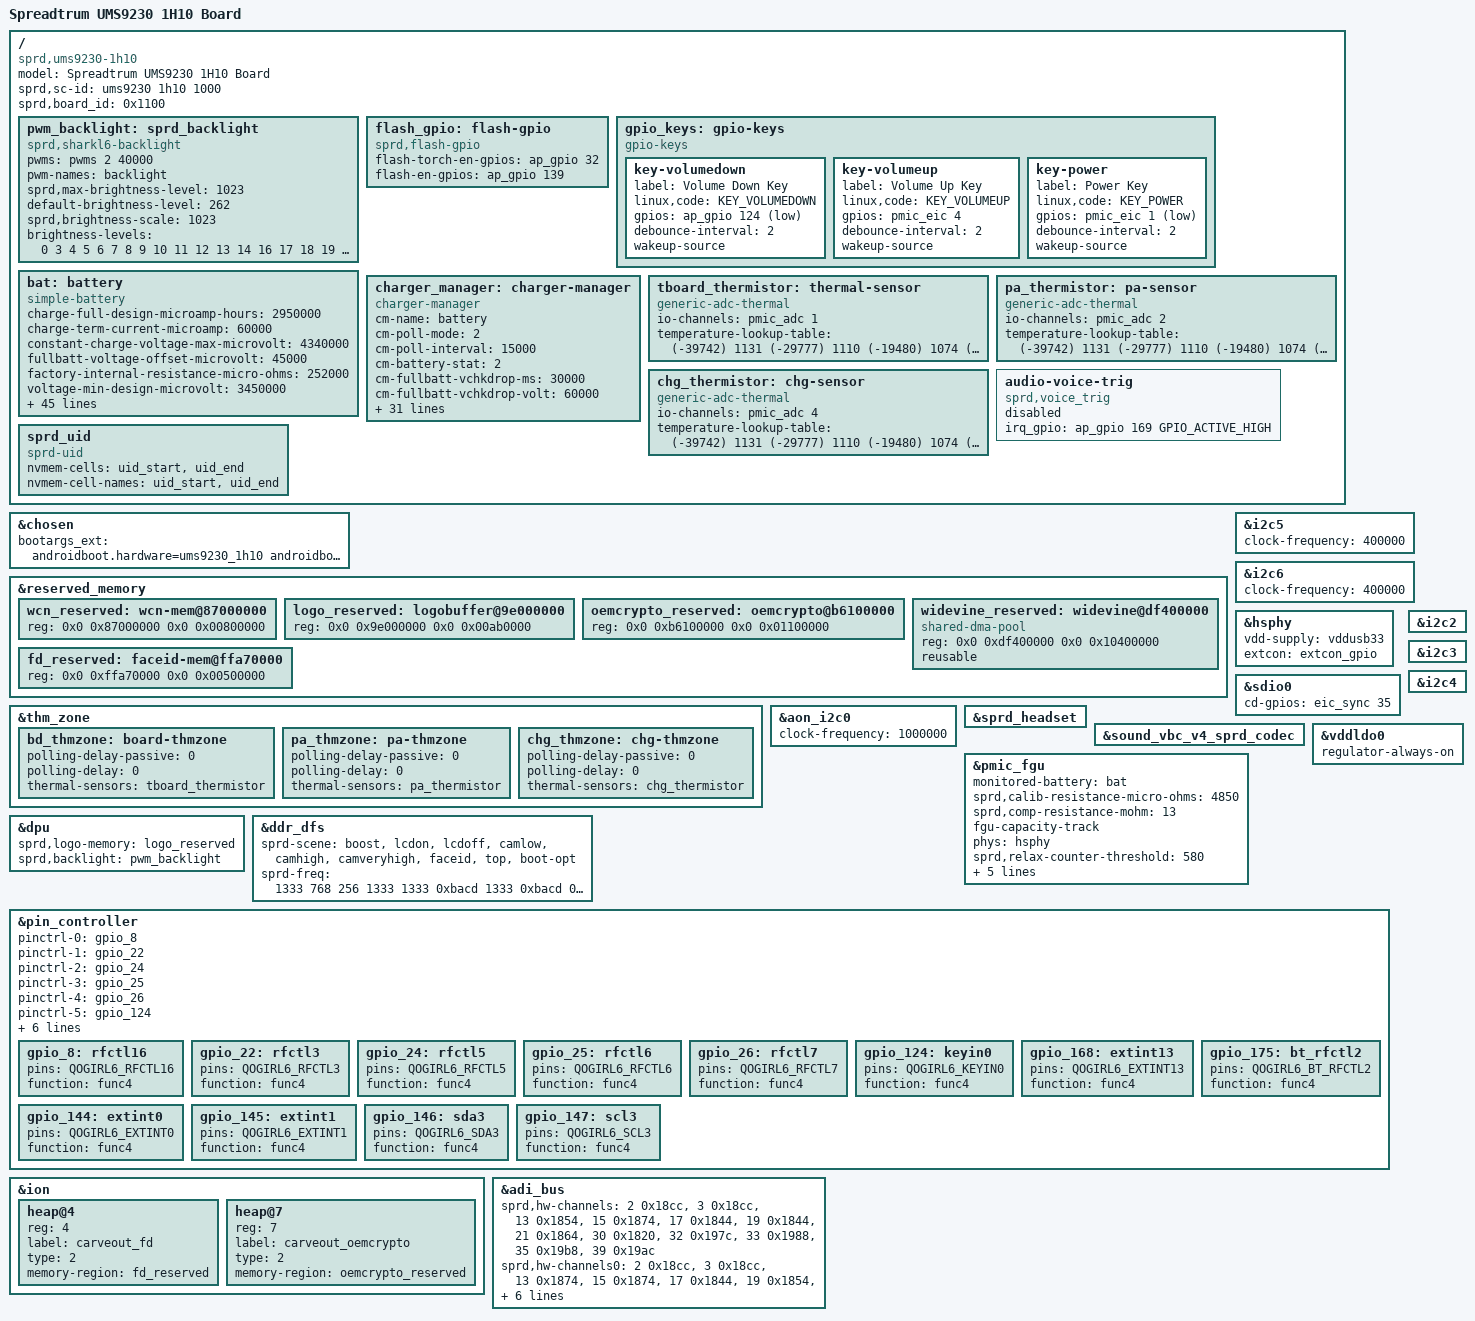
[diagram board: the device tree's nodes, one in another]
/dts-v1/;
/plugin/;
#include <dt-bindings/input/input.h>
#include <dt-bindings/gpio/gpio.h>
#include <dt-bindings/interrupt-controller/arm-gic.h>
#include <dt-bindings/clock/sprd,ums9230-clk.h>
#include <dt-bindings/mfd/sprd,sc2730-regs.h>
#include <dt-bindings/mfd/sprd,sc2730-mask.h>
#include <dt-bindings/usb/pd.h>
#include "ums9230-wcn.dtsi"
#include "lcd/lcd_dummy_mipi.dtsi"

/ {

	model = "Spreadtrum UMS9230 1H10 Board";

	compatible = "sprd,ums9230-1h10";

	sprd,sc-id = "ums9230 1h10 1000";

	sprd,board_id = <0x1100>; //XX00:base board,XX00~XXFF:customize board

	fragment {
		target-path = "/";
		__overlay__ {
			pwm_backlight: sprd_backlight {
				compatible = "sprd,sharkl6-backlight";
				pwms = <&pwms 2 40000>;
				pwm-names = "backlight";
				sprd,max-brightness-level = <1023>;
				default-brightness-level = <262>;
				sprd,brightness-scale = <1023>;
				brightness-levels = <
							  0   3   4   5   6   7
					  8   9  10  11  12  13  14  16  17  18
					 19  20  21  22  23  24  25  26  27  28
					 29  31  33  35  37  39  41  43  45  47
					 48  50  52  54  56  58  60  62  64  67
					 69  72  74  76  78  80  82  84  86  88
					 90  92  94  96  98 100 102 104 107 109
					112 114 116 118 120 122 124 126 128 130
					132 134 136 138 140 142 144 147 149 151
					154 156 158 160 162 164 166 168 170 172
					175 178 181 184 187 190 193 196 199 203
					205 208 211 214 217 220 223 226 229 234
					237 240 243 247 250 253 256 259 263 266
					269 270 274 277 280 283 287 290 294 297
					300 303 307 310 314 318 325 329 334 339
					340 343 347 350 354 358 365 369 374 380
					382 385 389 392 396 400 407 411 416 422
					426 430 434 438 442 446 452 457 460 464
					470 474 480 486 492 498 504 508 512 516
					522 527 532 536 540 545 550 555 561 568
					574 579 584 589 594 600 605 610 615 620
					625 630 635 641 647 652 657 662 667 673
					688 694 700 706 712 716 720 725 730 735
					740 746 752 758 764 770 776 782 790 798
					803 810 817 825 832 840 845 850 855 861
					866 872 878 884 890 896 903 911 918 924
				>;
			};

			flash_gpio: flash-gpio {
				compatible = "sprd,flash-gpio";
				flash-torch-en-gpios = <&ap_gpio 32 0>;
				flash-en-gpios = <&ap_gpio 139 0>;
			};

/*
			fingerprint@0 {
				compatible = "microarray,afs121";
				fpint-gpios = <&eic_async 29 0>;
			};
*/

			gpio_keys: gpio-keys {
				compatible = "gpio-keys";

				key-volumedown {
					label = "Volume Down Key";
					linux,code = <KEY_VOLUMEDOWN>;
					gpios = <&ap_gpio 124 GPIO_ACTIVE_LOW>;
					debounce-interval = <2>;
					wakeup-source;
				};

				key-volumeup {
					label = "Volume Up Key";
					linux,code = <KEY_VOLUMEUP>;
					gpios = <&pmic_eic 4 GPIO_ACTIVE_HIGH>;
					debounce-interval = <2>;
					wakeup-source;
				};

				key-power {
					label = "Power Key";
					linux,code = <KEY_POWER>;
					gpios = <&pmic_eic 1 GPIO_ACTIVE_LOW>;
					debounce-interval = <2>;
					wakeup-source;
				};
			};

			bat: battery {
				compatible = "simple-battery";
				charge-full-design-microamp-hours = <2950000>;
				charge-term-current-microamp = <60000>;
				constant-charge-voltage-max-microvolt = <4340000>;
				fullbatt-voltage-offset-microvolt = <45000>;
				factory-internal-resistance-micro-ohms = <252000>;
				voltage-min-design-microvolt = <3450000>;
				fast-charge-threshold-microvolt = <4100000>;
				fullbatt-voltage = <4300000>;
				fullbatt-current = <120000>;
				first-fullbatt-current = <150000>;
				fullbatt-track-end-vol = <4295000>;
				fullbatt-track-end-cur = <130000>;
				first-calib-voltage = <3580000>;
				first-calib-capacity = <50>;
				ir-us-upper-limit-microvolt = <4500000>;
				ir-cv-offset-microvolt = <100000>;
				ir-rc-micro-ohms = <20000>;

				ocv-capacity-celsius = <20>;
				ocv-capacity-table-0 = <4313000 100>, <4254000 95>, <4201000 90>,
							<4151000 85>, <4102000 80>, <4060000 75>,
							<4006000 70>, <3973000 65>, <3930000 60>,
							<3882000 55>, <3851000 50>, <3829000 45>,
							<3810000 40>, <3795000 35>, <3781000 30>,
							<3765000 25>, <3746000 20>, <3722000 15>,
							<3694000 10>, <3682000 5>, <3400000 0>;
				voltage-temp-table = <1110270 800>, <999440 850>, <890430 900>,
							  <785590 950>, <687630 1000>, <598220 1050>,
							  <517680 1100>, <446100 1150>, <383390 1200>,
							  <328950 1250>, <281840 1300>, <241480 1350>,
							  <207030 1400>, <177580 1450>, <152490 1500>,
							  <131160 1550>, <113000 1600>, <97790 1650>;
				capacity-temp-table = <45 100>, <25 100>, <10 100>, <0 95>, <(-10) 90>;
				resistance-temp-table = <45 53>, <25 100>, <10 395>, <0 567>, <(-10) 793>;

/*
				battery-internal-resistance-celsius = <(-20)>, <(-10)>, <0>, <10>,
					<25>, <35>, <45>, <55>;
				battery-internal-resistance-table-0 = <1224>, <1224>, <1140>,
					<1084>, <1034>, <1001>, <994>, <992>, <992>, <992>,
					<996>, <1002>, <1010>, <1024>, <1045>, <1072>, <1180>,
					<1393>, <1756>, <2461>, <4272>;
				battery-internal-resistance-table-1 = <893>, <893>, <818>, <767>,
					<743>, <705>, <685>, <684>, <678>, <675>, <672>, <673>,
					<679>, <691>, <709>, <734>, <765>, <799>, <839>, <899>,
					<1092>;
				battery-internal-resistance-table-2 = <407>, <407>, <402>, <423>,
					<429>, <428>, <409>, <416>, <408>, <395>, <390>, <390>,
					<393>, <398>, <405>, <416>, <431>, <452>, <492>, <585>,
					<730>;
				battery-internal-resistance-table-3 = <381>, <381>, <378>, <371>,
					<366>, <374>, <358>, <364>, <349>, <332>, <327>, <329>,
					<334>, <340>, <350>, <366>, <386>, <417>, <475>, <585>,
					<771>;
				battery-internal-resistance-table-4 = <182>, <182>, <179>, <179>,
					<179>, <181>, <182>, <195>, <194>, <173>, <164>, <164>,
					<167>, <171>, <175>, <174>, <172>, <179>, <187>, <244>,
					<311>;
				battery-internal-resistance-table-5 = <168>, <168>, <175>, <172>,
					<171>, <171>, <173>, <184>, <176>, <153>, <147>, <147>,
					<150>, <153>, <156>, <152>, <149>, <154>, <158>, <206>,
					<255>;
				battery-internal-resistance-table-6 = <123>, <123>, <122>, <122>,
					<123>, <126>, <130>, <138>, <143>, <120>, <115>, <116>,
					<119>, <124>, <129>, <120>, <117>, <119>, <117>, <139>,
					<156>;
				battery-internal-resistance-table-7 = <106>, <106>, <106>, <106>,
					<108>, <110>, <113>, <119>, <128>, <107>, <104>, <105>,
					<108>, <112>, <117>, <107>, <106>, <107>, <105>, <127>,
					<140>;
				battery-internal-resistance-ocv-table = <4339000>, <4276000>,
					<4221000>, <4169000>, <4118000>, <4072000>, <4022000>,
					<3983000>, <3942000>, <3892000>, <3857000>, <3833000>,
					<3813000>, <3797000>, <3783000>, <3766000>, <3746000>,
					<3723000>, <3693000>, <3680000>, <3439000>;
*/

				charge-sdp-current-microamp = <500000 500000>;
				charge-dcp-current-microamp = <2000000 2500000>;
				charge-cdp-current-microamp = <1500000 1500000>;
				charge-unknown-current-microamp = <1050000 1050000>;
				charge-fchg-current-microamp = <3250000 2000000>;
				charge-flash-current-microamp = <5000000 2700000>;
				charge-wl-bpp-current-microamp = <1000000 1000000>;
				charge-wl-epp-current-microamp = <2000000 1000000>;

				cap-calib-energy-density-ocv-table = <3350000 3800000>, <4150000 4350000>;
				cap-track-energy-density-ocv-table = <3400000 3722000>;
			/*
				dcp-jeita-temp-table = <1000 1030 0 4340000>, <1150 1180 700000 4340000>,
					<1450 1420 2000000 4340000>, <1600 1570 700000 4100000>;
				sdp-jeita-temp-table = <1000 1030 0 4340000>, <1150 1180 500000 4340000>,
					<1450 1420 500000 4340000>, <1600 1570 500000 4100000>;
				cdp-jeita-temp-table = <1000 1030 0 4340000>, <1150 1180 700000 4340000>,
					<1450 1420 1500000 4340000>, <1600 1570 700000 4100000>;
				unknown-jeita-temp-table = <1000 1030 0 4340000>, <1150 1180 700000 4340000>,
					<1450 1420 1050000 4340000>, <1600 1570 700000 4100000>;
				fchg-jeita-temp-table = <1000 1030 0 4340000>, <1150 1180 700000 4340000>,
					<1450 1420 3250000 4340000>, <1600 1570 700000 4100000>;
				flash-jeita-temp-table = <1000 1030 0 4340000>, <1150 1180 1000000 4340000>,
					<1450 1420 5000000 4340000>, <1600 1570 1000000 4100000>;
				wl-bpp-jeita-temp-table = <1000 1030 0 4340000>, <1150 1180 500000 4340000>,
					<1450 1420 1000000 4340000>, <1600 1570 5000000 4100000>;
				wl-epp-jeita-temp-table = <1000 1030 0 4340000>, <1150 1180 500000 4340000>,
					<1450 1420 2000000 4340000>, <1600 1570 500000 4100000>;
			*/
			};

			charger_manager: charger-manager {
				compatible = "charger-manager";
				cm-name = "battery";
				cm-poll-mode = <2>;
				cm-poll-interval = <15000>;
				cm-battery-stat = <2>;

				cm-fullbatt-vchkdrop-ms = <30000>;
				cm-fullbatt-vchkdrop-volt = <60000>;
				cm-fullbatt-capacity = <100>;
				/*Charge pump target charge current*/
				cm-cp-taper-current = <1000000>;

				cm-chargers = "aw32207_charger";
				/*
				cm-charge-pumps = "bq2597x-standalone";
				cm-wireless-chargers = "nu1619_wireless_charger";
				cm-wireless-charge-pump-converters = "hl1506_cp_converter";
				*/
				cm-fuel-gauge = "sc27xx-fgu";

				/* in deci centigrade */
				cm-battery-cold = <200>;
				cm-battery-cold-in-minus;
				cm-battery-hot = <800>;
				cm-battery-temp-diff = <100>;

				/* Allow charging for 6hr */
				cm-charging-max = <21600000>;
				/* recovery charging after stop charging 45min */
				cm-discharging-max = <2700000>;

				/* the interval to feed charger watchdog */
				cm-wdt-interval = <60>;

				/* drop voltage in microVolts to allow shutdown */
				cm-shutdown-voltage = <3100000>;

				/* when 99% of the time is exceeded, it will be forced to 100% */
				cm-tickle-time-out = <1500>;

				/* how much time to allow capacity change */
				cm-one-cap-time = <30>;
				cm-thermal-zone = "board-thmzone";
				/* when the safe charging voltage is exceeded, stop charging */
				cm-charge-voltage-max = <6500000>;
				cm-fast-charge-voltage-max = <10500000>;
				cm-flash-charge-voltage-max = <12000000>;
				cm-wireless-charge-voltage-max = <6500000>;
				cm-wireless-fast-charge-voltage-max = <12000000>;
				/* drop voltage in microVolts to restart charging */
				cm-charge-voltage-drop = <700000>;
				cm-fast-charge-voltage-drop = <700000>;
				cm-flash-charge-voltage-drop = <1000000>;
				cm-wireless-charge-voltage-drop = <700000>;
				cm-wireless-fast-charge-voltage-drop = <1000000>;

				/* sprd_fchg parameter */
/*
				sprd,support-fchg;
				sprd,support-pd-pps;
				sprd,pd-fixed-max-microwatt = <18000000>;
*/

				cm-cap-remap-table = <1 2 3>, <2 3 2>, <98 99 2>, <99 100 3>;

				monitored-battery = <&bat>;
				cm-keep-awake;

				phys = <&hsphy>;
/*
				extcon = <&pmic_typec>, <&pmic_pd>;
				pd-extcon-enable;
*/
				extcon = <&pmic_typec>;
			};

			tboard_thermistor: thermal-sensor {
				compatible = "generic-adc-thermal";
				#thermal-sensor-cells = <0>;
				io-channels = <&pmic_adc 1>;
				io-channel-names = "sensor-channel";
				temperature-lookup-table = <
					(-39742) 1131
					(-29777) 1110
					(-19480) 1074
					(-4679) 983
					10110 838
					24805 654
					44922 413
					54903 316
					64895 238
					74884 178
					84883 133
					94883 100
					104880 75
					114889 57
					124872 43 >;
			};

			pa_thermistor: pa-sensor {
				compatible = "generic-adc-thermal";
				#thermal-sensor-cells = <0>;
				io-channels = <&pmic_adc 2>;
				io-channel-names = "sensor-channel";
				temperature-lookup-table = <
					(-39742) 1131
					(-29777) 1110
					(-19480) 1074
					(-4679) 983
					10110 838
					24805 654
					44922 413
					54903 316
					64895 238
					74884 178
					84883 133
					94883 100
					104880 75
					114889 57
					124872 43 >;
			};

			chg_thermistor: chg-sensor {
				compatible = "generic-adc-thermal";
				#thermal-sensor-cells = <0>;
				io-channels = <&pmic_adc 4>;
				io-channel-names = "sensor-channel";
				temperature-lookup-table = <
					(-39742) 1131
					(-29777) 1110
					(-19480) 1074
					(-4679) 983
					10110 838
					24805 654
					44922 413
					54903 316
					64895 238
					74884 178
					84883 133
					94883 100
					104880 75
					114889 57
					124872 43 >;
			};

			audio-voice-trig {
				status = "disable";
				compatible = "sprd,voice_trig";
				irq_gpio = <&ap_gpio 169 GPIO_ACTIVE_HIGH>;
			};

			sprd_uid {
				compatible = "sprd-uid";
				nvmem-cells = <&uid_start>, <&uid_end>;
				nvmem-cell-names = "uid_start", "uid_end";
			};

		};
	};
};

&chosen {
	bootargs_ext = "androidboot.hardware=ums9230_1h10 androidboot.dtbo_idx=0";
};

&reserved_memory {
	#address-cells = <2>;
	#size-cells = <2>;
	wcn_reserved: wcn-mem@87000000 {
		reg = <0x0 0x87000000 0x0 0x00800000>;
	};

	logo_reserved: logobuffer@9e000000{
		reg = <0x0 0x9e000000 0x0 0x00ab0000>;
	};
	/* Encrypt and decrypt widevine video */
	oemcrypto_reserved: oemcrypto@b6100000 {
		reg = <0x0 0xb6100000 0x0 0x01100000>;
	};

	/*Set 8M after widevine to prevent memory out of bounds*/
	widevine_reserved: widevine@df400000 {
		compatible = "shared-dma-pool";
		reg = <0x0 0xdf400000 0x0 0x10400000>;
		reusable;
	};

	fd_reserved: faceid-mem@ffa70000 {
		reg = <0x0 0xffa70000 0x0 0x00500000>;
	};
};

&thm_zone {
	bd_thmzone: board-thmzone {
		polling-delay-passive = <0>;
		polling-delay = <0>;
		thermal-sensors = <&tboard_thermistor>;
	};

	pa_thmzone: pa-thmzone {
		polling-delay-passive = <0>;
		polling-delay = <0>;
		thermal-sensors = <&pa_thermistor>;
	};

	chg_thmzone: chg-thmzone {
		polling-delay-passive = <0>;
		polling-delay = <0>;
		thermal-sensors = <&chg_thermistor>;
	};
};

&i2c5 {
	status = "okay";
	clock-frequency = <400000>;
	#address-cells = <1>;
	#size-cells = <0>;

/*
	flash_ic: flash-ic@63 {
		compatible = "sprd,flash-ocp8137";
		reg = <0x63>;
		sprd,flash-ic = <8137>;
		sprd,torch = <1>;
		sprd,preflash = <1>;
		sprd,highlight = <1>;
		sprd,torch-level = <128>;
		sprd,preflash-level = <128>;
		sprd,highlight-level = <128>;
		sprd,lvfm-enable = <1>;
		flash-torch-en-gpios = <&ap_gpio 32 0>;
		flash-chip-en-gpios = <&ap_gpio 138 0>;
		flash-en-gpios = <&ap_gpio 139 0>;
		flash-sync-gpios = <&ap_gpio 121 0>;
	};
*/

};

&i2c6 {
	status = "okay";
	clock-frequency = <400000>;
	#address-cells = <1>;
	#size-cells = <0>;

};

&hsphy {
	vdd-supply = <&vddusb33>;
	extcon = <&extcon_gpio>;
/*
	sprd,hsphy-device-eye-pattern = <0x0613d1c0>;
	sprd,hsphy-host-eye-pattern = <0x04f3d1c0>;
*/
	status = "okay";
};

/*
&usb {
	extcon = <&extcon_gpio>, <&pmic_typec>;
	vbus-supply = <&vddvbus>;
	status = "okay";
};
*/

&sdio0 {
	cd-gpios = <&eic_sync 35 GPIO_ACTIVE_HIGH>;
};

&i2c2 {
	status = "okay";
	#address-cells = <1>;
	#size-cells = <0>;
};

&i2c3 {
	status = "okay";
	#address-cells = <1>;
	#size-cells = <0>;
};

&i2c4 {
	status = "okay";
	#address-cells = <1>;
	#size-cells = <0>;

};

&aon_i2c0 {
	status = "okay";
	clock-frequency = <1000000>;
};

&sprd_headset {
	status = "okay";

/*
	extcon = <&pmic_typec>;
	mic-gpios = <&ap_gpio 175 GPIO_ACTIVE_HIGH>;
	lr-gpios = <&ap_gpio 174 GPIO_ACTIVE_HIGH>;
	sprd,3pole-adc-threshold = <112>;
*/

};


&sound_vbc_v4_sprd_codec {
	status = "okay";
};

&vddldo0 {
	regulator-always-on;
};

&pmic_fgu {
	monitored-battery = <&bat>;
	sprd,calib-resistance-micro-ohms = <4850>;
	sprd,comp-resistance-mohm = <13>;

	fgu-capacity-track;
	phys = <&hsphy>;

	sprd,relax-counter-threshold = <580>;
	sprd,relax-current-threshold = <30>;
	sprd,capacity-sleep-calibration;

	sprd,capacity-boot-calibration;
	sprd,capacity-charge-cycle;
	sprd,basp;
};

/*
&panel {
	sprd,backlight = <&pwm_backlight>;
	avdd-gpio = <&ap_gpio 135 GPIO_ACTIVE_HIGH>;
	avee-gpio = <&ap_gpio 136 GPIO_ACTIVE_HIGH>;
	reset-gpio = <&ap_gpio 50 GPIO_ACTIVE_HIGH>;
};
*/

&dpu {
	sprd,logo-memory = <&logo_reserved>;

	sprd,backlight = <&pwm_backlight>;
};

/*
&pmic_fchg {
	status = "okay";
	sprd,input-voltage-microvolt = <5000000>;
};

&pmic_pd {
	status = "okay";
	usb_con: connector {
		compatible = "usb-c-connector";
		label = "USB-C";
		power-role = "dual";
		try-power-role = "sink";
		source-pdos = <PDO_FIXED(5000, 400, PDO_FIXED_USB_COMM)>;
		sink-pdos = <PDO_FIXED(5000, 3000, PDO_FIXED_USB_COMM)
			     PDO_PPS_APDO(3300, 11000, 3000)>;
		op-sink-microwatt = <10000000>;
	};
};
*/

&ddr_dfs {
	  sprd-scene = "boost", "lcdon", "lcdoff", "camlow",
			"camhigh", "camveryhigh", "faceid", "top", "boot-opt";
	  sprd-freq = <1333 768 256 1333 1333 0xbacd 1333 0xbacd 0xbacd>;
};

&pin_controller {
	pinctrl-names =
	/* rfctl16 ,rfctl3, rfctl5 */
	"gpio_8", "gpio_22", "gpio_24",
	/* rfctl6, rfctl7, keyin0 */
	"gpio_25", "gpio_26", "gpio_124",
	/* bt_rfctl2, gpio_168 */
	"gpio_175", "gpio_168",
	/*revo add ctp int reset sda scl*/
	"gpio_144", "gpio_145", "gpio_146", "gpio_147";
	
	pinctrl-0 = <&gpio_8>;
	pinctrl-1 = <&gpio_22>;
	pinctrl-2 = <&gpio_24>;
	pinctrl-3 = <&gpio_25>;
	pinctrl-4 = <&gpio_26>;
	pinctrl-5 = <&gpio_124>;
	pinctrl-6 = <&gpio_175>;
	pinctrl-7 = <&gpio_168>;
	
	/*revo add ctp int reset sda scl*/
	pinctrl-8 = <&gpio_144>;
	pinctrl-9 = <&gpio_145>;
	pinctrl-10 = <&gpio_146>;
	pinctrl-11 = <&gpio_147>;

	gpio_8: rfctl16 {
		pins = "QOGIRL6_RFCTL16";
		function = "func4";
	};

	gpio_22: rfctl3 {
		pins = "QOGIRL6_RFCTL3";
		function = "func4";
	};

	gpio_24: rfctl5 {
		pins = "QOGIRL6_RFCTL5";
		function = "func4";
	};

	gpio_25: rfctl6 {
		pins = "QOGIRL6_RFCTL6";
		function = "func4";
	};

	gpio_26: rfctl7 {
		pins = "QOGIRL6_RFCTL7";
		function = "func4";
	};

	gpio_124: keyin0 {
		pins = "QOGIRL6_KEYIN0";
		function = "func4";
	};
	gpio_168: extint13 {
		pins = "QOGIRL6_EXTINT13";
		function = "func4";
	};
	gpio_175: bt_rfctl2 {
		pins = "QOGIRL6_BT_RFCTL2";
		function = "func4";
	};
	
	/*revo add ctp int reset sda scl*/
	gpio_144: extint0 {
		pins = "QOGIRL6_EXTINT0";
		function = "func4";
	};
	gpio_145: extint1 {
		pins = "QOGIRL6_EXTINT1";
		function = "func4";
	};
	gpio_146: sda3 {
		pins = "QOGIRL6_SDA3";
		function = "func4";
	};
	gpio_147: scl3 {
		pins = "QOGIRL6_SCL3";
		function = "func4";
	};
	
};

&ion {
	#address-cells = <1>;
	#size-cells = <0>;

	heap@4 {
		reg = <4>;
		label = "carveout_fd";
		type = <2>;
		memory-region = <&fd_reserved>;
	};

	heap@7 {
		reg = <7>;
		label = "carveout_oemcrypto";
		type = <2>;
		memory-region = <&oemcrypto_reserved>;
	};
};

&adi_bus {
	sprd,hw-channels = <2 0x18cc>, <3 0x18cc>, <13 0x1854>, <15 0x1874>,
			<17 0x1844>, <19 0x1844>, <21 0x1864>, <30 0x1820>,
			<32 0x197c>, <33 0x1988>, <35 0x19b8>, <39 0x19ac>;
	sprd,hw-channels0 = <2 0x18cc>, <3 0x18cc>, <13 0x1874>, <15 0x1874>,
			<17 0x1844>, <19 0x1854>, <21 0x1864>, <30 0x1820>,
			<32 0x197c>, <33 0x1988>, <35 0x19b8>, <39 0x19ac>;
	sprd,hw-channels1 = <2 0x18cc>, <3 0x18cc>, <13 0x1854>, <15 0x1874>,
			<17 0x1844>, <19 0x1844>, <21 0x1864>, <30 0x1820>,
			<32 0x197c>, <33 0x1988>, <35 0x19b8>, <39 0x19ac>;
};

